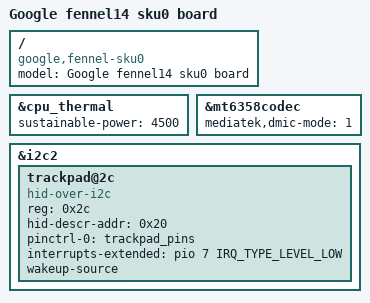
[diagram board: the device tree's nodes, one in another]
// SPDX-License-Identifier: (GPL-2.0 OR MIT)
/*
 * Copyright 2020 Google LLC
 */

/dts-v1/;
#include "mt8183-kukui-jacuzzi.dtsi"
#include "mt8183-kukui-audio-da7219-rt1015p.dtsi"

/ {
	model = "Google fennel14 sku0 board";
	compatible = "google,fennel-sku0", "google,fennel", "mediatek,mt8183";
};

&cpu_thermal {
	sustainable-power = <4500>; /* milliwatts */
};

&mt6358codec {
	mediatek,dmic-mode = <1>; /* one-wire */
};

&i2c2 {
	trackpad@2c {
		compatible = "hid-over-i2c";
		reg = <0x2c>;
		hid-descr-addr = <0x20>;

		pinctrl-names = "default";
		pinctrl-0 = <&trackpad_pins>;

		interrupts-extended = <&pio 7 IRQ_TYPE_LEVEL_LOW>;

		wakeup-source;
	};
};
